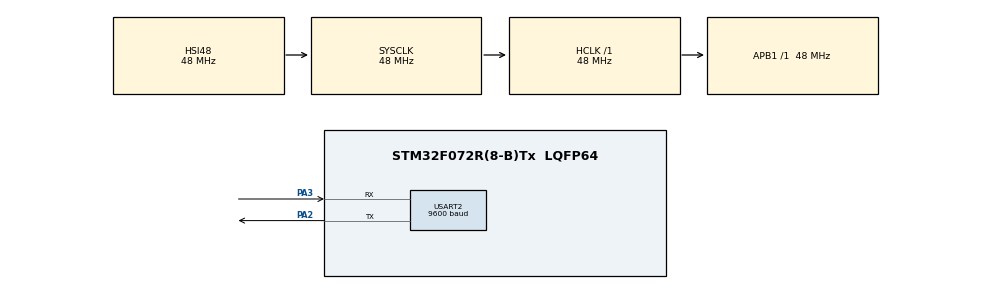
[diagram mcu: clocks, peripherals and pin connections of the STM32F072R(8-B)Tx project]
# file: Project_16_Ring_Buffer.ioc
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Dma.Request0=USART2_RX
Dma.USART2_RX.0.Direction=DMA_PERIPH_TO_MEMORY
Dma.USART2_RX.0.Instance=DMA1_Channel5
Dma.USART2_RX.0.MemDataAlignment=DMA_MDATAALIGN_BYTE
Dma.USART2_RX.0.MemInc=DMA_MINC_ENABLE
Dma.USART2_RX.0.Mode=DMA_NORMAL
Dma.USART2_RX.0.PeriphDataAlignment=DMA_PDATAALIGN_BYTE
Dma.USART2_RX.0.PeriphInc=DMA_PINC_DISABLE
Dma.USART2_RX.0.Priority=DMA_PRIORITY_LOW
Mcu.Family=STM32F0
Mcu.Name=STM32F072R(8-B)Tx
Mcu.Package=LQFP64
NVIC.DMA1_Channel4_5_6_7_IRQn=true\:0\:0\:false\:false\:true\:false\:true\:true
NVIC.USART2_IRQn=true\:0\:0\:false\:false\:true\:true\:true\:true
PA2.Mode=Asynchronous
PA2.Signal=USART2_TX
PA3.Mode=Asynchronous
PA3.Signal=USART2_RX
PF0-OSC_IN.Mode=HSE-External-Oscillator
PF0-OSC_IN.Signal=RCC_OSC_IN
PF1-OSC_OUT.Mode=HSE-External-Oscillator
PF1-OSC_OUT.Signal=RCC_OSC_OUT
ProjectManager.HeapSize=0x200
ProjectManager.StackSize=0x400
ProjectManager.TargetToolchain=STM32CubeIDE
RCC.AHBFreq_Value=48000000
RCC.APB1Freq_Value=48000000
RCC.APB1TimFreq_Value=48000000
RCC.HCLKFreq_Value=48000000
RCC.PLLSourceVirtual=RCC_PLLSOURCE_HSE
RCC.SYSCLKFreq_VALUE=48000000
RCC.SYSCLKSource=RCC_SYSCLKSOURCE_HSI48
USART2.BaudRate=9600
USART2.VirtualMode-Asynchronous=VM_ASYNC
board=custom

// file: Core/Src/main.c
/* USER CODE BEGIN Header */
/**
  ******************************************************************************
  * @file           : main.c
  * @brief          : Main program body
  ******************************************************************************
  * @attention
  *
  * Copyright (c) 2022 STMicroelectronics.
  * All rights reserved.
  *
  * This software is licensed under terms that can be found in the LICENSE file
  * in the root directory of this software component.
  * If no LICENSE file comes with this software, it is provided AS-IS.
  *
  ******************************************************************************
  */
/* USER CODE END Header */
#include "main.h"

/* USER CODE BEGIN Includes */
#include "uartRingBufDMA.h"

/* USER CODE END Includes */

UART_HandleTypeDef huart2;
DMA_HandleTypeDef hdma_usart2_rx;

void SystemClock_Config(void);
static void MX_GPIO_Init(void);
static void MX_DMA_Init(void);
static void MX_USART2_UART_Init(void);

int main(void)
{

  /* MCU Configuration--------------------------------------------------------*/

  /* Reset of all peripherals, Initializes the Flash interface and the Systick. */
  HAL_Init();

  /* Configure the system clock */
  SystemClock_Config();

  /* Initialize all configured peripherals */
  MX_GPIO_Init();
  MX_DMA_Init();
  MX_USART2_UART_Init();
  /* USER CODE BEGIN 2 */

  Ringbuf_Init();

  /*if(isConfirmed(5000) != 1)
  {

	  Error_Handler();

  }

  */

  if (waitFor("Hello",6000)!= 1)
  {

	  Error_Handler();

  }

  /* USER CODE END 2 */

  /* Infinite loop */
  while (1)
  {

	  HAL_Delay(1000);

  }
}

void SystemClock_Config(void)
{
  RCC_OscInitTypeDef RCC_OscInitStruct = {0};
  RCC_ClkInitTypeDef RCC_ClkInitStruct = {0};
  RCC_PeriphCLKInitTypeDef PeriphClkInit = {0};

  /** Initializes the RCC Oscillators according to the specified parameters
  * in the RCC_OscInitTypeDef structure.
  */
  RCC_OscInitStruct.OscillatorType = RCC_OSCILLATORTYPE_HSI48;
  RCC_OscInitStruct.HSI48State = RCC_HSI48_ON;
  RCC_OscInitStruct.PLL.PLLState = RCC_PLL_NONE;
  if (HAL_RCC_OscConfig(&RCC_OscInitStruct) != HAL_OK)
  {
    Error_Handler();
  }

  /** Initializes the CPU, AHB and APB buses clocks
  */
  RCC_ClkInitStruct.ClockType = RCC_CLOCKTYPE_HCLK|RCC_CLOCKTYPE_SYSCLK
                              |RCC_CLOCKTYPE_PCLK1;
  RCC_ClkInitStruct.SYSCLKSource = RCC_SYSCLKSOURCE_HSI48;
  RCC_ClkInitStruct.AHBCLKDivider = RCC_SYSCLK_DIV1;
  RCC_ClkInitStruct.APB1CLKDivider = RCC_HCLK_DIV1;

  if (HAL_RCC_ClockConfig(&RCC_ClkInitStruct, FLASH_LATENCY_1) != HAL_OK)
  {
    Error_Handler();
  }
  PeriphClkInit.PeriphClockSelection = RCC_PERIPHCLK_USART2;
  PeriphClkInit.Usart2ClockSelection = RCC_USART2CLKSOURCE_PCLK1;
  if (HAL_RCCEx_PeriphCLKConfig(&PeriphClkInit) != HAL_OK)
  {
    Error_Handler();
  }
}

static void MX_USART2_UART_Init(void)
{

  huart2.Instance = USART2;
  huart2.Init.BaudRate = 9600;
  huart2.Init.WordLength = UART_WORDLENGTH_8B;
  huart2.Init.StopBits = UART_STOPBITS_1;
  huart2.Init.Parity = UART_PARITY_NONE;
  huart2.Init.Mode = UART_MODE_TX_RX;
  huart2.Init.HwFlowCtl = UART_HWCONTROL_NONE;
  huart2.Init.OverSampling = UART_OVERSAMPLING_16;
  huart2.Init.OneBitSampling = UART_ONE_BIT_SAMPLE_DISABLE;
  huart2.AdvancedInit.AdvFeatureInit = UART_ADVFEATURE_NO_INIT;
  if (HAL_UART_Init(&huart2) != HAL_OK)
  {
    Error_Handler();
  }

}

static void MX_DMA_Init(void)
{

  /* DMA controller clock enable */
  __HAL_RCC_DMA1_CLK_ENABLE();

  /* DMA interrupt init */
  /* DMA1_Channel4_5_6_7_IRQn interrupt configuration */
  HAL_NVIC_SetPriority(DMA1_Channel4_5_6_7_IRQn, 0, 0);
  HAL_NVIC_EnableIRQ(DMA1_Channel4_5_6_7_IRQn);

}

static void MX_GPIO_Init(void)
{

  /* GPIO Ports Clock Enable */
  __HAL_RCC_GPIOF_CLK_ENABLE();
  __HAL_RCC_GPIOA_CLK_ENABLE();

}

void Error_Handler(void)
{
  __disable_irq();
  while (1)
  {
  }
}
